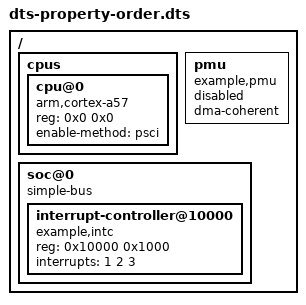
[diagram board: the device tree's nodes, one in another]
// SPDX-License-Identifier: GPL-2.0-only OR BSD-2-Clause
/*
 * Test fixture: Incorrect property order
 */

/dts-v1/;

/ {
	cpus {
		#address-cells = <1>;
		#size-cells = <0>;

		cpu@0 {
			device_type = "cpu";
			compatible = "arm,cortex-a57";
			reg = <0x0 0x0>;
			enable-method = "psci";
		};
	};

	pmu {
		compatible = "example,pmu";
		dma-coherent;

		status = "disabled";
	};

	soc@0 {
		compatible = "simple-bus";
		ranges = <0 0 0 0xc0000000>;

		#address-cells = <1>;
		#size-cells = <1>;

		interrupt-controller@10000 {
			compatible = "example,intc";
			reg = <0x10000 0x1000>;
			interrupts = <1 2 3>;
		};
	};
};
